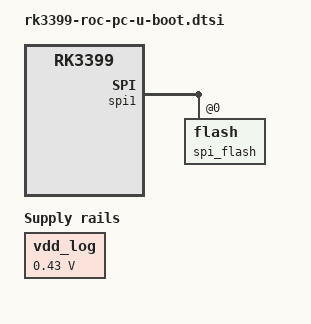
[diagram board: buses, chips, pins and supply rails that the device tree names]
// SPDX-License-Identifier: GPL-2.0+
/*
 * Copyright (C) 2019 Levin Du <djw@t-chip.com.cn>
 */

#include "rk3399-u-boot.dtsi"
#include "rk3399-sdram-lpddr4-100.dtsi"

/ {
	aliases {
		spi0 = &spi1;
	};

	config {
		u-boot,spl-payload-offset = <0x40000>; /* @ 256KB */
	};

	chosen {
		u-boot,spl-boot-order = "same-as-spl", &spi_flash, &sdhci, &sdmmc;
	};
};

&spi1 {
	spi_flash: flash@0 {
		u-boot,dm-pre-reloc;
	};
};

&vdd_log {
	regulator-min-microvolt = <430000>;
	regulator-init-microvolt = <950000>;
};
